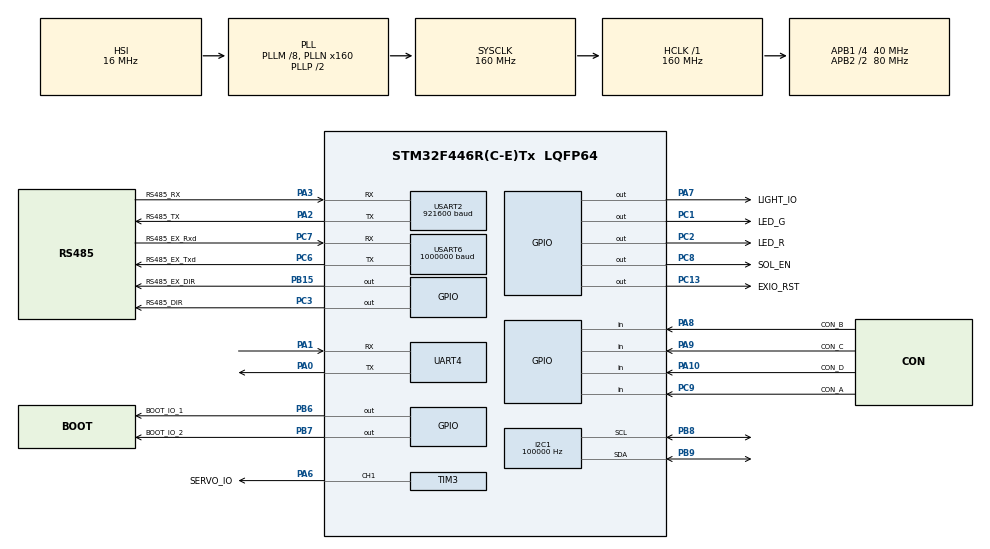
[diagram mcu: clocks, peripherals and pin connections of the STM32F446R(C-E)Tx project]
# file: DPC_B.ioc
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Dma.Request0=UART4_RX
Dma.Request1=UART4_TX
Dma.Request2=USART2_TX
Dma.Request3=USART2_RX
Dma.Request4=USART6_RX
Dma.Request5=USART6_TX
Dma.UART4_RX.0.Direction=DMA_PERIPH_TO_MEMORY
Dma.UART4_RX.0.FIFOMode=DMA_FIFOMODE_DISABLE
Dma.UART4_RX.0.Instance=DMA1_Stream2
Dma.UART4_RX.0.MemDataAlignment=DMA_MDATAALIGN_BYTE
Dma.UART4_RX.0.MemInc=DMA_MINC_ENABLE
Dma.UART4_RX.0.Mode=DMA_CIRCULAR
Dma.UART4_RX.0.PeriphDataAlignment=DMA_PDATAALIGN_BYTE
Dma.UART4_RX.0.PeriphInc=DMA_PINC_DISABLE
Dma.UART4_RX.0.Priority=DMA_PRIORITY_LOW
Dma.UART4_TX.1.Direction=DMA_MEMORY_TO_PERIPH
Dma.UART4_TX.1.FIFOMode=DMA_FIFOMODE_DISABLE
Dma.UART4_TX.1.Instance=DMA1_Stream4
Dma.UART4_TX.1.MemDataAlignment=DMA_MDATAALIGN_BYTE
Dma.UART4_TX.1.MemInc=DMA_MINC_ENABLE
Dma.UART4_TX.1.Mode=DMA_NORMAL
Dma.UART4_TX.1.PeriphDataAlignment=DMA_PDATAALIGN_BYTE
Dma.UART4_TX.1.PeriphInc=DMA_PINC_DISABLE
Dma.UART4_TX.1.Priority=DMA_PRIORITY_LOW
Dma.USART2_RX.3.Direction=DMA_PERIPH_TO_MEMORY
Dma.USART2_RX.3.FIFOMode=DMA_FIFOMODE_DISABLE
Dma.USART2_RX.3.Instance=DMA1_Stream5
Dma.USART2_RX.3.MemDataAlignment=DMA_MDATAALIGN_BYTE
Dma.USART2_RX.3.MemInc=DMA_MINC_ENABLE
Dma.USART2_RX.3.Mode=DMA_CIRCULAR
Dma.USART2_RX.3.PeriphDataAlignment=DMA_PDATAALIGN_BYTE
Dma.USART2_RX.3.PeriphInc=DMA_PINC_DISABLE
Dma.USART2_RX.3.Priority=DMA_PRIORITY_LOW
Dma.USART2_TX.2.Direction=DMA_MEMORY_TO_PERIPH
Dma.USART2_TX.2.FIFOMode=DMA_FIFOMODE_DISABLE
Dma.USART2_TX.2.Instance=DMA1_Stream6
Dma.USART2_TX.2.MemDataAlignment=DMA_MDATAALIGN_BYTE
Dma.USART2_TX.2.MemInc=DMA_MINC_ENABLE
Dma.USART2_TX.2.Mode=DMA_NORMAL
Dma.USART2_TX.2.PeriphDataAlignment=DMA_PDATAALIGN_BYTE
Dma.USART2_TX.2.PeriphInc=DMA_PINC_DISABLE
Dma.USART2_TX.2.Priority=DMA_PRIORITY_LOW
Dma.USART6_RX.4.Direction=DMA_PERIPH_TO_MEMORY
Dma.USART6_RX.4.FIFOMode=DMA_FIFOMODE_DISABLE
Dma.USART6_RX.4.Instance=DMA2_Stream1
Dma.USART6_RX.4.MemDataAlignment=DMA_MDATAALIGN_BYTE
Dma.USART6_RX.4.MemInc=DMA_MINC_ENABLE
Dma.USART6_RX.4.Mode=DMA_CIRCULAR
Dma.USART6_RX.4.PeriphDataAlignment=DMA_PDATAALIGN_BYTE
Dma.USART6_RX.4.PeriphInc=DMA_PINC_DISABLE
Dma.USART6_RX.4.Priority=DMA_PRIORITY_LOW
Dma.USART6_TX.5.Direction=DMA_MEMORY_TO_PERIPH
Dma.USART6_TX.5.FIFOMode=DMA_FIFOMODE_DISABLE
Dma.USART6_TX.5.Instance=DMA2_Stream6
Dma.USART6_TX.5.MemDataAlignment=DMA_MDATAALIGN_BYTE
Dma.USART6_TX.5.MemInc=DMA_MINC_ENABLE
Dma.USART6_TX.5.Mode=DMA_NORMAL
Dma.USART6_TX.5.PeriphDataAlignment=DMA_PDATAALIGN_BYTE
Dma.USART6_TX.5.PeriphInc=DMA_PINC_DISABLE
Dma.USART6_TX.5.Priority=DMA_PRIORITY_LOW
FREERTOS.Mutexes01=ResmapMutex,Dynamic,NULL,Available
FREERTOS.Tasks01=defaultTask,24,512,StartDefaultTask,Default,NULL,Dynamic,NULL,NULL;controlTask,24,1024,StartControl,Default,NULL,Dynamic,NULL,NULL;rs485Task,24,512,Startrs485,Default,NULL,Dynamic,NULL,NULL;i2cTask,8,512,Start_i2c,Default,NULL,Dynamic,NULL,NULL;dpcaTask,24,512,StartDPCA,Default,NULL,Dynamic,NULL,NULL;systemTask,24,1024,StartSystem,Default,NULL,Dynamic,NULL,NULL;periTask,24,512,StartPeri,Default,NULL,Dynamic,NULL,NULL
FREERTOS.configTOTAL_HEAP_SIZE=30720
FREERTOS.configUSE_NEWLIB_REENTRANT=1
I2C1.ClockSpeed=100000
Mcu.Family=STM32F4
Mcu.Name=STM32F446R(C-E)Tx
Mcu.Package=LQFP64
NVIC.DMA1_Stream2_IRQn=true\:5\:0\:false\:false\:true\:true\:false\:true\:true
NVIC.DMA1_Stream4_IRQn=true\:5\:0\:false\:false\:true\:true\:false\:true\:true
NVIC.DMA1_Stream5_IRQn=true\:5\:0\:false\:false\:true\:true\:false\:true\:true
NVIC.DMA1_Stream6_IRQn=true\:5\:0\:false\:false\:true\:true\:false\:true\:true
NVIC.DMA2_Stream1_IRQn=true\:5\:0\:false\:false\:true\:true\:false\:true\:true
NVIC.DMA2_Stream6_IRQn=true\:5\:0\:false\:false\:true\:true\:false\:true\:true
NVIC.PriorityGroup=NVIC_PRIORITYGROUP_4
NVIC.TIM6_DAC_IRQn=true\:15\:0\:false\:false\:true\:false\:false\:true\:true
NVIC.TimeBase=TIM6_DAC_IRQn
NVIC.TimeBaseIP=TIM6
NVIC.UART4_IRQn=true\:5\:0\:false\:false\:true\:true\:true\:true\:true
NVIC.USART2_IRQn=true\:5\:0\:false\:false\:true\:true\:true\:true\:true
NVIC.USART6_IRQn=true\:5\:0\:false\:false\:true\:true\:true\:true\:true
PA0-WKUP.Mode=Asynchronous
PA0-WKUP.Signal=UART4_TX
PA1.Mode=Asynchronous
PA1.Signal=UART4_RX
PA10.GPIO_Label=CON_D
PA10.Signal=GPIO_Input
PA13.Mode=Trace_Asynchronous_SW
PA13.Signal=SYS_JTMS-SWDIO
PA14.Mode=Trace_Asynchronous_SW
PA14.Signal=SYS_JTCK-SWCLK
PA2.GPIO_Label=RS485_TX
PA2.Mode=Asynchronous
PA2.Signal=USART2_TX
PA3.GPIO_Label=RS485_RX
PA3.Mode=Asynchronous
PA3.Signal=USART2_RX
PA6.GPIO_Label=SERVO_IO
PA6.Signal=S_TIM3_CH1
PA7.GPIO_Label=LIGHT_IO
PA7.Signal=GPIO_Output
PA8.GPIO_Label=CON_B
PA8.Signal=GPIO_Input
PA9.GPIO_Label=CON_C
PA9.Signal=GPIO_Input
PB15.GPIO_Label=RS485_EX_DIR
PB15.Signal=GPIO_Output
PB3.Mode=Trace_Asynchronous_SW
PB3.Signal=SYS_JTDO-SWO
PB6.GPIO_Label=BOOT_IO_1
PB6.Signal=GPIO_Output
PB7.GPIO_Label=BOOT_IO_2
PB7.Signal=GPIO_Output
PB8.GPIO_Pu=GPIO_PULLUP
PB8.Mode=I2C
PB8.Signal=I2C1_SCL
PB9.GPIO_Pu=GPIO_PULLUP
PB9.Mode=I2C
PB9.Signal=I2C1_SDA
PC1.GPIO_Label=LED_G
PC1.Signal=GPIO_Output
PC13.GPIO_Label=EXIO_RST
PC13.Signal=GPIO_Output
PC2.GPIO_Label=LED_R
PC2.Signal=GPIO_Output
PC3.GPIO_Label=RS485_DIR
PC3.Signal=GPIO_Output
PC6.GPIO_Label=RS485_EX_Txd
PC6.Mode=Asynchronous
PC6.Signal=USART6_TX
PC7.GPIO_Label=RS485_EX_Rxd
PC7.Mode=Asynchronous
PC7.Signal=USART6_RX
PC8.GPIO_Label=SOL_EN
PC8.Signal=GPIO_Output
PC9.GPIO_Label=CON_A
PC9.Signal=GPIO_Input
ProjectManager.HeapSize=0x200
ProjectManager.StackSize=0x400
ProjectManager.TargetToolchain=STM32CubeIDE
RCC.AHBFreq_Value=160000000
RCC.APB1CLKDivider=RCC_HCLK_DIV4
RCC.APB1Freq_Value=40000000
RCC.APB1TimFreq_Value=80000000
RCC.APB2CLKDivider=RCC_HCLK_DIV2
RCC.APB2Freq_Value=80000000
RCC.APB2TimFreq_Value=160000000
RCC.CortexFreq_Value=160000000
RCC.HCLKFreq_Value=160000000
RCC.PLLM=8
RCC.PLLN=160
RCC.SYSCLKFreq_VALUE=160000000
RCC.SYSCLKSource=RCC_SYSCLKSOURCE_PLLCLK
RCC.USBFreq_Value=160000000
RCC.VCOOutputFreq_Value=320000000
SH.S_TIM3_CH1.0=TIM3_CH1,PWM Generation1 CH1
TIM3.Channel-PWM\ Generation1\ CH1=TIM_CHANNEL_1
TIM3.Period=20000-1
TIM3.Prescaler=79
TIM5.Prescaler=80-1
TIM8.Period=1000-1
TIM8.Prescaler=8-1
UART4.VirtualMode=Asynchronous
USART2.BaudRate=921600
USART2.VirtualMode=VM_ASYNC
USART6.BaudRate=1000000
USART6.VirtualMode=VM_ASYNC
VP_FREERTOS_VS_CMSIS_V2.Mode=CMSIS_V2
VP_SYS_VS_tim6.Mode=TIM6
VP_TIM14_VS_ClockSourceINT.Mode=Enable_Timer
VP_TIM3_VS_ClockSourceINT.Mode=Internal
VP_TIM5_VS_ClockSourceINT.Mode=Internal
VP_TIM8_VS_ClockSourceINT.Mode=Internal
board=custom

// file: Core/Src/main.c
/* USER CODE BEGIN Header */
/**
  ******************************************************************************
  * @file           : main.c
  * @brief          : Main program body
  ******************************************************************************
  * @attention
  *
  * Copyright (c) 2025 STMicroelectronics.
  * All rights reserved.
  *
  * This software is licensed under terms that can be found in the LICENSE file
  * in the root directory of this software component.
  * If no LICENSE file comes with this software, it is provided AS-IS.
  *
  ******************************************************************************
  */
/* USER CODE END Header */
#include "main.h"
#include "cmsis_os.h"

/* USER CODE BEGIN Includes */
#include "rd_system.h"
/* USER CODE END Includes */

I2C_HandleTypeDef hi2c1;

TIM_HandleTypeDef htim3;
TIM_HandleTypeDef htim5;
TIM_HandleTypeDef htim8;
TIM_HandleTypeDef htim14;

UART_HandleTypeDef huart4;
UART_HandleTypeDef huart2;
UART_HandleTypeDef huart6;
DMA_HandleTypeDef hdma_uart4_rx;
DMA_HandleTypeDef hdma_uart4_tx;
DMA_HandleTypeDef hdma_usart2_tx;
DMA_HandleTypeDef hdma_usart2_rx;
DMA_HandleTypeDef hdma_usart6_rx;
DMA_HandleTypeDef hdma_usart6_tx;

/* Definitions for defaultTask */
osThreadId_t defaultTaskHandle;
const osThreadAttr_t defaultTask_attributes = {
  .name = "defaultTask",
  .stack_size = 512 * 4,
  .priority = (osPriority_t) osPriorityNormal,
};
/* Definitions for controlTask */
osThreadId_t controlTaskHandle;
const osThreadAttr_t controlTask_attributes = {
  .name = "controlTask",
  .stack_size = 1024 * 4,
  .priority = (osPriority_t) osPriorityNormal,
};
/* Definitions for rs485Task */
osThreadId_t rs485TaskHandle;
const osThreadAttr_t rs485Task_attributes = {
  .name = "rs485Task",
  .stack_size = 512 * 4,
  .priority = (osPriority_t) osPriorityNormal,
};
/* Definitions for i2cTask */
osThreadId_t i2cTaskHandle;
const osThreadAttr_t i2cTask_attributes = {
  .name = "i2cTask",
  .stack_size = 512 * 4,
  .priority = (osPriority_t) osPriorityLow,
};
/* Definitions for dpcaTask */
osThreadId_t dpcaTaskHandle;
const osThreadAttr_t dpcaTask_attributes = {
  .name = "dpcaTask",
  .stack_size = 512 * 4,
  .priority = (osPriority_t) osPriorityNormal,
};
/* Definitions for systemTask */
osThreadId_t systemTaskHandle;
const osThreadAttr_t systemTask_attributes = {
  .name = "systemTask",
  .stack_size = 1024 * 4,
  .priority = (osPriority_t) osPriorityNormal,
};
/* Definitions for periTask */
osThreadId_t periTaskHandle;
const osThreadAttr_t periTask_attributes = {
  .name = "periTask",
  .stack_size = 512 * 4,
  .priority = (osPriority_t) osPriorityNormal,
};
/* Definitions for ResmapMutex */
osMutexId_t ResmapMutexHandle;
const osMutexAttr_t ResmapMutex_attributes = {
  .name = "ResmapMutex"
};
/* USER CODE BEGIN PV */
/* 전역 변수는 rd_system.c 에 정의. rd_system.h 의 extern 선언으로 접근. */
/* USER CODE END PV */

void SystemClock_Config(void);
static void MX_GPIO_Init(void);
static void MX_DMA_Init(void);
static void MX_TIM8_Init(void);
static void MX_UART4_Init(void);
static void MX_USART2_UART_Init(void);
static void MX_TIM3_Init(void);
static void MX_I2C1_Init(void);
static void MX_TIM5_Init(void);
static void MX_TIM14_Init(void);
static void MX_USART6_UART_Init(void);
void StartDefaultTask(void *argument);
void StartControl(void *argument);
void Startrs485(void *argument);
void Start_i2c(void *argument);
void StartDPCA(void *argument);
void StartSystem(void *argument);
void StartPeri(void *argument);

int main(void)
{

  /* MCU Configuration--------------------------------------------------------*/

  /* Reset of all peripherals, Initializes the Flash interface and the Systick. */
  HAL_Init();

  /* Configure the system clock */
  SystemClock_Config();

  /* USER CODE BEGIN SysInit */
  HAL_Delay(100);
  /* USER CODE END SysInit */

  /* Initialize all configured peripherals */
  MX_GPIO_Init();
  MX_DMA_Init();
  MX_TIM8_Init();
  MX_UART4_Init();
  MX_USART2_UART_Init();
  MX_TIM3_Init();
  MX_I2C1_Init();
  MX_TIM5_Init();
  MX_TIM14_Init();
  MX_USART6_UART_Init();
  /* USER CODE BEGIN 2 */

  RD_SYSTEM_INIT();
  /* USER CODE END 2 */

  /* Init scheduler */
  osKernelInitialize();
  /* Create the mutex(es) */
  /* creation of ResmapMutex */
  ResmapMutexHandle = osMutexNew(&ResmapMutex_attributes);

  /* Create the thread(s) */
  /* creation of defaultTask */
  defaultTaskHandle = osThreadNew(StartDefaultTask, NULL, &defaultTask_attributes);

  /* creation of controlTask */
  controlTaskHandle = osThreadNew(StartControl, NULL, &controlTask_attributes);

  /* creation of rs485Task */
  rs485TaskHandle = osThreadNew(Startrs485, NULL, &rs485Task_attributes);

  /* creation of i2cTask */
  i2cTaskHandle = osThreadNew(Start_i2c, NULL, &i2cTask_attributes);

  /* creation of dpcaTask */
  dpcaTaskHandle = osThreadNew(StartDPCA, NULL, &dpcaTask_attributes);

  /* creation of systemTask */
  systemTaskHandle = osThreadNew(StartSystem, NULL, &systemTask_attributes);

  /* creation of periTask */
  periTaskHandle = osThreadNew(StartPeri, NULL, &periTask_attributes);

  /* Start scheduler */
  osKernelStart();

  /* We should never get here as control is now taken by the scheduler */

  /* Infinite loop */
  while (1)
  {

  }
}

void SystemClock_Config(void)
{
  RCC_OscInitTypeDef RCC_OscInitStruct = {0};
  RCC_ClkInitTypeDef RCC_ClkInitStruct = {0};

  /** Configure the main internal regulator output voltage
  */
  __HAL_RCC_PWR_CLK_ENABLE();
  __HAL_PWR_VOLTAGESCALING_CONFIG(PWR_REGULATOR_VOLTAGE_SCALE1);

  /** Initializes the RCC Oscillators according to the specified parameters
  * in the RCC_OscInitTypeDef structure.
  */
  RCC_OscInitStruct.OscillatorType = RCC_OSCILLATORTYPE_HSI;
  RCC_OscInitStruct.HSIState = RCC_HSI_ON;
  RCC_OscInitStruct.HSICalibrationValue = RCC_HSICALIBRATION_DEFAULT;
  RCC_OscInitStruct.PLL.PLLState = RCC_PLL_ON;
  RCC_OscInitStruct.PLL.PLLSource = RCC_PLLSOURCE_HSI;
  RCC_OscInitStruct.PLL.PLLM = 8;
  RCC_OscInitStruct.PLL.PLLN = 160;
  RCC_OscInitStruct.PLL.PLLP = RCC_PLLP_DIV2;
  RCC_OscInitStruct.PLL.PLLQ = 2;
  RCC_OscInitStruct.PLL.PLLR = 2;
  if (HAL_RCC_OscConfig(&RCC_OscInitStruct) != HAL_OK)
  {
    Error_Handler();
  }

  /** Initializes the CPU, AHB and APB buses clocks
  */
  RCC_ClkInitStruct.ClockType = RCC_CLOCKTYPE_HCLK|RCC_CLOCKTYPE_SYSCLK
                              |RCC_CLOCKTYPE_PCLK1|RCC_CLOCKTYPE_PCLK2;
  RCC_ClkInitStruct.SYSCLKSource = RCC_SYSCLKSOURCE_PLLCLK;
  RCC_ClkInitStruct.AHBCLKDivider = RCC_SYSCLK_DIV1;
  RCC_ClkInitStruct.APB1CLKDivider = RCC_HCLK_DIV4;
  RCC_ClkInitStruct.APB2CLKDivider = RCC_HCLK_DIV2;

  if (HAL_RCC_ClockConfig(&RCC_ClkInitStruct, FLASH_LATENCY_5) != HAL_OK)
  {
    Error_Handler();
  }
}

static void MX_I2C1_Init(void)
{

  hi2c1.Instance = I2C1;
  hi2c1.Init.ClockSpeed = 100000;
  hi2c1.Init.DutyCycle = I2C_DUTYCYCLE_2;
  hi2c1.Init.OwnAddress1 = 0;
  hi2c1.Init.AddressingMode = I2C_ADDRESSINGMODE_7BIT;
  hi2c1.Init.DualAddressMode = I2C_DUALADDRESS_DISABLE;
  hi2c1.Init.OwnAddress2 = 0;
  hi2c1.Init.GeneralCallMode = I2C_GENERALCALL_DISABLE;
  hi2c1.Init.NoStretchMode = I2C_NOSTRETCH_DISABLE;
  if (HAL_I2C_Init(&hi2c1) != HAL_OK)
  {
    Error_Handler();
  }

}

static void MX_TIM3_Init(void)
{

  TIM_ClockConfigTypeDef sClockSourceConfig = {0};
  TIM_MasterConfigTypeDef sMasterConfig = {0};
  TIM_OC_InitTypeDef sConfigOC = {0};

  htim3.Instance = TIM3;
  htim3.Init.Prescaler = 79;
  htim3.Init.CounterMode = TIM_COUNTERMODE_UP;
  htim3.Init.Period = 20000-1;
  htim3.Init.ClockDivision = TIM_CLOCKDIVISION_DIV1;
  htim3.Init.AutoReloadPreload = TIM_AUTORELOAD_PRELOAD_DISABLE;
  if (HAL_TIM_Base_Init(&htim3) != HAL_OK)
  {
    Error_Handler();
  }
  sClockSourceConfig.ClockSource = TIM_CLOCKSOURCE_INTERNAL;
  if (HAL_TIM_ConfigClockSource(&htim3, &sClockSourceConfig) != HAL_OK)
  {
    Error_Handler();
  }
  if (HAL_TIM_PWM_Init(&htim3) != HAL_OK)
  {
    Error_Handler();
  }
  sMasterConfig.MasterOutputTrigger = TIM_TRGO_RESET;
  sMasterConfig.MasterSlaveMode = TIM_MASTERSLAVEMODE_DISABLE;
  if (HAL_TIMEx_MasterConfigSynchronization(&htim3, &sMasterConfig) != HAL_OK)
  {
    Error_Handler();
  }
  sConfigOC.OCMode = TIM_OCMODE_PWM1;
  sConfigOC.Pulse = 0;
  sConfigOC.OCPolarity = TIM_OCPOLARITY_HIGH;
  sConfigOC.OCFastMode = TIM_OCFAST_DISABLE;
  if (HAL_TIM_PWM_ConfigChannel(&htim3, &sConfigOC, TIM_CHANNEL_1) != HAL_OK)
  {
    Error_Handler();
  }
  HAL_TIM_MspPostInit(&htim3);

}

static void MX_TIM5_Init(void)
{

  TIM_ClockConfigTypeDef sClockSourceConfig = {0};
  TIM_MasterConfigTypeDef sMasterConfig = {0};

  htim5.Instance = TIM5;
  htim5.Init.Prescaler = 80-1;
  htim5.Init.CounterMode = TIM_COUNTERMODE_UP;
  htim5.Init.Period = 4294967295;
  htim5.Init.ClockDivision = TIM_CLOCKDIVISION_DIV1;
  htim5.Init.AutoReloadPreload = TIM_AUTORELOAD_PRELOAD_DISABLE;
  if (HAL_TIM_Base_Init(&htim5) != HAL_OK)
  {
    Error_Handler();
  }
  sClockSourceConfig.ClockSource = TIM_CLOCKSOURCE_INTERNAL;
  if (HAL_TIM_ConfigClockSource(&htim5, &sClockSourceConfig) != HAL_OK)
  {
    Error_Handler();
  }
  sMasterConfig.MasterOutputTrigger = TIM_TRGO_RESET;
  sMasterConfig.MasterSlaveMode = TIM_MASTERSLAVEMODE_DISABLE;
  if (HAL_TIMEx_MasterConfigSynchronization(&htim5, &sMasterConfig) != HAL_OK)
  {
    Error_Handler();
  }

}

static void MX_TIM8_Init(void)
{

  TIM_ClockConfigTypeDef sClockSourceConfig = {0};
  TIM_MasterConfigTypeDef sMasterConfig = {0};

  htim8.Instance = TIM8;
  htim8.Init.Prescaler = 8-1;
  htim8.Init.CounterMode = TIM_COUNTERMODE_UP;
  htim8.Init.Period = 1000-1;
  htim8.Init.ClockDivision = TIM_CLOCKDIVISION_DIV1;
  htim8.Init.RepetitionCounter = 0;
  htim8.Init.AutoReloadPreload = TIM_AUTORELOAD_PRELOAD_DISABLE;
  if (HAL_TIM_Base_Init(&htim8) != HAL_OK)
  {
    Error_Handler();
  }
  sClockSourceConfig.ClockSource = TIM_CLOCKSOURCE_INTERNAL;
  if (HAL_TIM_ConfigClockSource(&htim8, &sClockSourceConfig) != HAL_OK)
  {
    Error_Handler();
  }
  sMasterConfig.MasterOutputTrigger = TIM_TRGO_RESET;
  sMasterConfig.MasterSlaveMode = TIM_MASTERSLAVEMODE_DISABLE;
  if (HAL_TIMEx_MasterConfigSynchronization(&htim8, &sMasterConfig) != HAL_OK)
  {
    Error_Handler();
  }

}

static void MX_TIM14_Init(void)
{

  htim14.Instance = TIM14;
  htim14.Init.Prescaler = 0;
  htim14.Init.CounterMode = TIM_COUNTERMODE_UP;
  htim14.Init.Period = 65535;
  htim14.Init.ClockDivision = TIM_CLOCKDIVISION_DIV1;
  htim14.Init.AutoReloadPreload = TIM_AUTORELOAD_PRELOAD_DISABLE;
  if (HAL_TIM_Base_Init(&htim14) != HAL_OK)
  {
    Error_Handler();
  }

}

static void MX_UART4_Init(void)
{

  huart4.Instance = UART4;
  huart4.Init.BaudRate = 115200;
  huart4.Init.WordLength = UART_WORDLENGTH_8B;
  huart4.Init.StopBits = UART_STOPBITS_1;
  huart4.Init.Parity = UART_PARITY_NONE;
  huart4.Init.Mode = UART_MODE_TX_RX;
  huart4.Init.HwFlowCtl = UART_HWCONTROL_NONE;
  huart4.Init.OverSampling = UART_OVERSAMPLING_16;
  if (HAL_UART_Init(&huart4) != HAL_OK)
  {
    Error_Handler();
  }

}

static void MX_USART2_UART_Init(void)
{

  huart2.Instance = USART2;
  huart2.Init.BaudRate = 921600;
  huart2.Init.WordLength = UART_WORDLENGTH_8B;
  huart2.Init.StopBits = UART_STOPBITS_1;
  huart2.Init.Parity = UART_PARITY_NONE;
  huart2.Init.Mode = UART_MODE_TX_RX;
  huart2.Init.HwFlowCtl = UART_HWCONTROL_NONE;
  huart2.Init.OverSampling = UART_OVERSAMPLING_16;
  if (HAL_UART_Init(&huart2) != HAL_OK)
  {
    Error_Handler();
  }

}

static void MX_USART6_UART_Init(void)
{

  huart6.Instance = USART6;
  huart6.Init.BaudRate = 1000000;
  huart6.Init.WordLength = UART_WORDLENGTH_8B;
  huart6.Init.StopBits = UART_STOPBITS_1;
  huart6.Init.Parity = UART_PARITY_NONE;
  huart6.Init.Mode = UART_MODE_TX_RX;
  huart6.Init.HwFlowCtl = UART_HWCONTROL_NONE;
  huart6.Init.OverSampling = UART_OVERSAMPLING_16;
  if (HAL_UART_Init(&huart6) != HAL_OK)
  {
    Error_Handler();
  }

}

static void MX_DMA_Init(void)
{

  /* DMA controller clock enable */
  __HAL_RCC_DMA1_CLK_ENABLE();
  __HAL_RCC_DMA2_CLK_ENABLE();

  /* DMA interrupt init */
  /* DMA1_Stream2_IRQn interrupt configuration */
  HAL_NVIC_SetPriority(DMA1_Stream2_IRQn, 5, 0);
  HAL_NVIC_EnableIRQ(DMA1_Stream2_IRQn);
  /* DMA1_Stream4_IRQn interrupt configuration */
  HAL_NVIC_SetPriority(DMA1_Stream4_IRQn, 5, 0);
  HAL_NVIC_EnableIRQ(DMA1_Stream4_IRQn);
  /* DMA1_Stream5_IRQn interrupt configuration */
  HAL_NVIC_SetPriority(DMA1_Stream5_IRQn, 5, 0);
  HAL_NVIC_EnableIRQ(DMA1_Stream5_IRQn);
  /* DMA1_Stream6_IRQn interrupt configuration */
  HAL_NVIC_SetPriority(DMA1_Stream6_IRQn, 5, 0);
  HAL_NVIC_EnableIRQ(DMA1_Stream6_IRQn);
  /* DMA2_Stream1_IRQn interrupt configuration */
  HAL_NVIC_SetPriority(DMA2_Stream1_IRQn, 5, 0);
  HAL_NVIC_EnableIRQ(DMA2_Stream1_IRQn);
  /* DMA2_Stream6_IRQn interrupt configuration */
  HAL_NVIC_SetPriority(DMA2_Stream6_IRQn, 5, 0);
  HAL_NVIC_EnableIRQ(DMA2_Stream6_IRQn);

}

static void MX_GPIO_Init(void)
{
  GPIO_InitTypeDef GPIO_InitStruct = {0};

  /* GPIO Ports Clock Enable */
  __HAL_RCC_GPIOC_CLK_ENABLE();
  __HAL_RCC_GPIOA_CLK_ENABLE();
  __HAL_RCC_GPIOB_CLK_ENABLE();

  /*Configure GPIO pin Output Level */
  HAL_GPIO_WritePin(GPIOC, EXIO_RST_Pin|LED_G_Pin|LED_R_Pin|RS485_DIR_Pin
                          |SOL_EN_Pin, GPIO_PIN_RESET);

  /*Configure GPIO pin Output Level */
  HAL_GPIO_WritePin(LIGHT_IO_GPIO_Port, LIGHT_IO_Pin, GPIO_PIN_RESET);

  /*Configure GPIO pin Output Level */
  HAL_GPIO_WritePin(GPIOB, RS485_EX_DIR_Pin|BOOT_IO_1_Pin|BOOT_IO_2_Pin, GPIO_PIN_RESET);

  /*Configure GPIO pins : EXIO_RST_Pin LED_G_Pin LED_R_Pin RS485_DIR_Pin
                           SOL_EN_Pin */
  GPIO_InitStruct.Pin = EXIO_RST_Pin|LED_G_Pin|LED_R_Pin|RS485_DIR_Pin
                          |SOL_EN_Pin;
  GPIO_InitStruct.Mode = GPIO_MODE_OUTPUT_PP;
  GPIO_InitStruct.Pull = GPIO_NOPULL;
  GPIO_InitStruct.Speed = GPIO_SPEED_FREQ_LOW;
  HAL_GPIO_Init(GPIOC, &GPIO_InitStruct);

  /*Configure GPIO pin : LIGHT_IO_Pin */
  GPIO_InitStruct.Pin = LIGHT_IO_Pin;
  GPIO_InitStruct.Mode = GPIO_MODE_OUTPUT_PP;
  GPIO_InitStruct.Pull = GPIO_NOPULL;
  GPIO_InitStruct.Speed = GPIO_SPEED_FREQ_LOW;
  HAL_GPIO_Init(LIGHT_IO_GPIO_Port, &GPIO_InitStruct);

  /*Configure GPIO pins : RS485_EX_DIR_Pin BOOT_IO_1_Pin BOOT_IO_2_Pin */
  GPIO_InitStruct.Pin = RS485_EX_DIR_Pin|BOOT_IO_1_Pin|BOOT_IO_2_Pin;
  GPIO_InitStruct.Mode = GPIO_MODE_OUTPUT_PP;
  GPIO_InitStruct.Pull = GPIO_NOPULL;
  GPIO_InitStruct.Speed = GPIO_SPEED_FREQ_LOW;
  HAL_GPIO_Init(GPIOB, &GPIO_InitStruct);

  /*Configure GPIO pin : CON_A_Pin */
  GPIO_InitStruct.Pin = CON_A_Pin;
  GPIO_InitStruct.Mode = GPIO_MODE_INPUT;
  GPIO_InitStruct.Pull = GPIO_NOPULL;
  HAL_GPIO_Init(CON_A_GPIO_Port, &GPIO_InitStruct);

  /*Configure GPIO pins : CON_B_Pin CON_C_Pin CON_D_Pin */
  GPIO_InitStruct.Pin = CON_B_Pin|CON_C_Pin|CON_D_Pin;
  GPIO_InitStruct.Mode = GPIO_MODE_INPUT;
  GPIO_InitStruct.Pull = GPIO_NOPULL;
  HAL_GPIO_Init(GPIOA, &GPIO_InitStruct);

}

/* USER CODE BEGIN 4 */
/* HAL_UART_ErrorCallback → rd_system.c 로 이동 */
/* USER CODE END 4 */

void StartDefaultTask(void *argument)
{
  /* USER CODE BEGIN 5 */
  RD_TASK_DEFAULT();
  /* USER CODE END 5 */
}

void StartControl(void *argument)
{
  /* USER CODE BEGIN StartControl */
  RD_TASK_CONTROL();
  /* USER CODE END StartControl */
}

void Startrs485(void *argument)
{
  /* USER CODE BEGIN Startrs485 */
  RD_TASK_RS485();
  /* USER CODE END Startrs485 */
}

void Start_i2c(void *argument)
{
  /* USER CODE BEGIN Start_i2c */
  RD_TASK_I2C();
  /* USER CODE END Start_i2c */
}

void StartDPCA(void *argument)
{
  /* USER CODE BEGIN StartDPCA */
  RD_TASK_DPCA();
  /* USER CODE END StartDPCA */
}

void StartSystem(void *argument)
{
  /* USER CODE BEGIN StartSystem */
  /* Infinite loop */
  RD_TASK_SYSTEM();
  /* USER CODE END StartSystem */
}

void StartPeri(void *argument)
{
  /* USER CODE BEGIN StartPeri */
  RD_TASK_PERI();
  /* USER CODE END StartPeri */
}

void HAL_TIM_PeriodElapsedCallback(TIM_HandleTypeDef *htim)
{
  if (htim->Instance == TIM6)
  {
    HAL_IncTick();
  }
}

void Error_Handler(void)
{
  __disable_irq();
  while (1)
  {
  }
}
